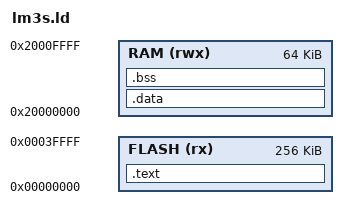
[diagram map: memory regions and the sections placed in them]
/* Linker script for the TI/Luminary LM3S6965 (qemu lm3s6965evb machine). */

ENTRY(Reset_Handler)

MEMORY
{
    FLASH (rx) : ORIGIN = 0x00000000, LENGTH = 256K
    RAM  (rwx) : ORIGIN = 0x20000000, LENGTH = 64K
}

SECTIONS
{
    .text :
    {
        KEEP(*(.isr_vector))
        *(.text*)
        *(.rodata*)
        *(.init)
        *(.fini)

        . = ALIGN(4);
        __start_test_cases = .;
        KEEP(*(test_cases))
        __stop_test_cases = .;

        . = ALIGN(4);
        __init_array_start = .;
        KEEP(*(SORT(.init_array.*)))
        KEEP(*(.init_array))
        __init_array_end = .;

        . = ALIGN(4);
        KEEP(*(.fini_array))
        KEEP(*(SORT(.fini_array.*)))

        *(.ARM.extab* .gnu.linkonce.armextab.*)
        . = ALIGN(4);
        __exidx_start = .;
        *(.ARM.exidx*)
        __exidx_end = .;

        . = ALIGN(4);
        __data_load = .;
    } > FLASH

    .data : AT (__data_load)
    {
        . = ALIGN(4);
        __data_start = .;
        *(.data*)
        . = ALIGN(4);
        __data_end = .;
    } > RAM

    .bss :
    {
        . = ALIGN(4);
        __bss_start = .;
        *(.bss*)
        *(COMMON)
        . = ALIGN(4);
        __bss_end = .;
    } > RAM

    . = ALIGN(8);
    __stack_top = ORIGIN(RAM) + LENGTH(RAM);
}
